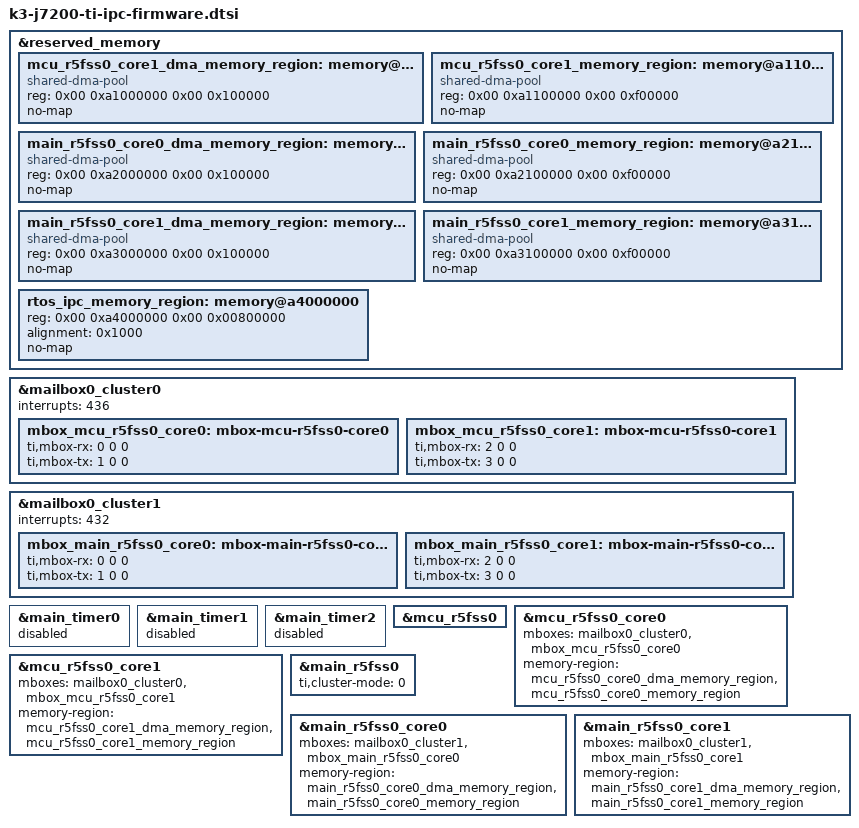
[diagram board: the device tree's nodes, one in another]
// SPDX-License-Identifier: GPL-2.0-only OR MIT
/**
 * Device Tree Source for enabling IPC using TI SDK firmware on J7200 SoCs
 *
 * Copyright (C) 2020-2025 Texas Instruments Incorporated - https://www.ti.com/
 */

&reserved_memory {
	mcu_r5fss0_core1_dma_memory_region: memory@a1000000 {
		compatible = "shared-dma-pool";
		reg = <0x00 0xa1000000 0x00 0x100000>;
		no-map;
	};

	mcu_r5fss0_core1_memory_region: memory@a1100000 {
		compatible = "shared-dma-pool";
		reg = <0x00 0xa1100000 0x00 0xf00000>;
		no-map;
	};

	main_r5fss0_core0_dma_memory_region: memory@a2000000 {
		compatible = "shared-dma-pool";
		reg = <0x00 0xa2000000 0x00 0x100000>;
		no-map;
	};

	main_r5fss0_core0_memory_region: memory@a2100000 {
		compatible = "shared-dma-pool";
		reg = <0x00 0xa2100000 0x00 0xf00000>;
		no-map;
	};

	main_r5fss0_core1_dma_memory_region: memory@a3000000 {
		compatible = "shared-dma-pool";
		reg = <0x00 0xa3000000 0x00 0x100000>;
		no-map;
	};

	main_r5fss0_core1_memory_region: memory@a3100000 {
		compatible = "shared-dma-pool";
		reg = <0x00 0xa3100000 0x00 0xf00000>;
		no-map;
	};

	rtos_ipc_memory_region: memory@a4000000 {
		reg = <0x00 0xa4000000 0x00 0x00800000>;
		alignment = <0x1000>;
		no-map;
	};
};

&mailbox0_cluster0 {
	status = "okay";
	interrupts = <436>;

	mbox_mcu_r5fss0_core0: mbox-mcu-r5fss0-core0 {
		ti,mbox-rx = <0 0 0>;
		ti,mbox-tx = <1 0 0>;
	};

	mbox_mcu_r5fss0_core1: mbox-mcu-r5fss0-core1 {
		ti,mbox-rx = <2 0 0>;
		ti,mbox-tx = <3 0 0>;
	};
};

&mailbox0_cluster1 {
	status = "okay";
	interrupts = <432>;

	mbox_main_r5fss0_core0: mbox-main-r5fss0-core0 {
		ti,mbox-rx = <0 0 0>;
		ti,mbox-tx = <1 0 0>;
	};

	mbox_main_r5fss0_core1: mbox-main-r5fss0-core1 {
		ti,mbox-rx = <2 0 0>;
		ti,mbox-tx = <3 0 0>;
	};
};

/* Timers are used by Remoteproc firmware */
&main_timer0 {
	status = "reserved";
};

&main_timer1 {
	status = "reserved";
};

&main_timer2 {
	status = "reserved";
};

&mcu_r5fss0 {
	status = "okay";
};

&mcu_r5fss0_core0 {
	mboxes = <&mailbox0_cluster0 &mbox_mcu_r5fss0_core0>;
	memory-region = <&mcu_r5fss0_core0_dma_memory_region>,
			<&mcu_r5fss0_core0_memory_region>;
	status = "okay";
};

&mcu_r5fss0_core1 {
	mboxes = <&mailbox0_cluster0 &mbox_mcu_r5fss0_core1>;
	memory-region = <&mcu_r5fss0_core1_dma_memory_region>,
			<&mcu_r5fss0_core1_memory_region>;
	status = "okay";
};

&main_r5fss0 {
	ti,cluster-mode = <0>;
	status = "okay";
};

&main_r5fss0_core0 {
	mboxes = <&mailbox0_cluster1 &mbox_main_r5fss0_core0>;
	memory-region = <&main_r5fss0_core0_dma_memory_region>,
			<&main_r5fss0_core0_memory_region>;
	status = "okay";
};

&main_r5fss0_core1 {
	mboxes = <&mailbox0_cluster1 &mbox_main_r5fss0_core1>;
	memory-region = <&main_r5fss0_core1_dma_memory_region>,
			<&main_r5fss0_core1_memory_region>;
	status = "okay";
};
